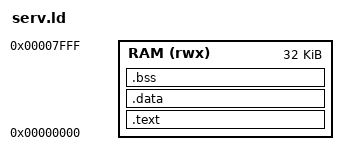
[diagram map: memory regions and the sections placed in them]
/* Simple linker script for SERV (RV32I) — RAM at 0x00000000 */
OUTPUT_FORMAT("elf32-littleriscv", "elf32-littleriscv", "elf32-littleriscv")
OUTPUT_ARCH(riscv)
ENTRY(_start)

MEMORY
{
    RAM (rwx) : ORIGIN = 0x00000000, LENGTH = 32K
}

SECTIONS
{
    .text : {
        *(.text.start)   /* startup.S _start must be first */
        *(.text*)
        *(.rodata*)
    } > RAM

    .data : {
        *(.data*)
        *(.sdata*)
    } > RAM

    .bss (NOLOAD) : {
        *(.bss*)
        *(.sbss*)
        *(COMMON)
    } > RAM

    /* Discard unnecessary sections */
    /DISCARD/ : {
        *(.comment)
        *(.note*)
        *(.eh_frame*)
    }
}
